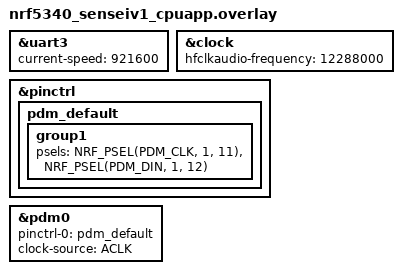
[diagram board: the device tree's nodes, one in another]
/*
 * Copyright (c) 2025 ETH Zurich and University of Bologna
 * SPDX-License-Identifier: Apache-2.0
 *
 * Device tree overlay for PDM microphone
 *
 * Connect your PDM microphone as follows:
 *   - CLK: P1.11 (microphone clock input)
 *   - DATA: P1.12 (microphone data output)
 *   - VDD: 1.8V or 3.3V (depending on your microphone)
 *   - GND: Ground
 */

/* Configure UART for logging at 921600 baud */
uart_gap: &uart3 {
    current-speed = <921600>;
};

&clock {
    hfclkaudio-frequency = <12288000>;
};

&pinctrl {
    pdm_default: pdm_default {
        group1 {
            psels = <NRF_PSEL(PDM_CLK, 1, 11)>,
                    <NRF_PSEL(PDM_DIN, 1, 12)>;
        };
    };
};

dmic_dev: &pdm0 {
    status = "okay";
    pinctrl-0 = <&pdm_default>;
    pinctrl-names = "default";
    clock-source = "ACLK";
};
